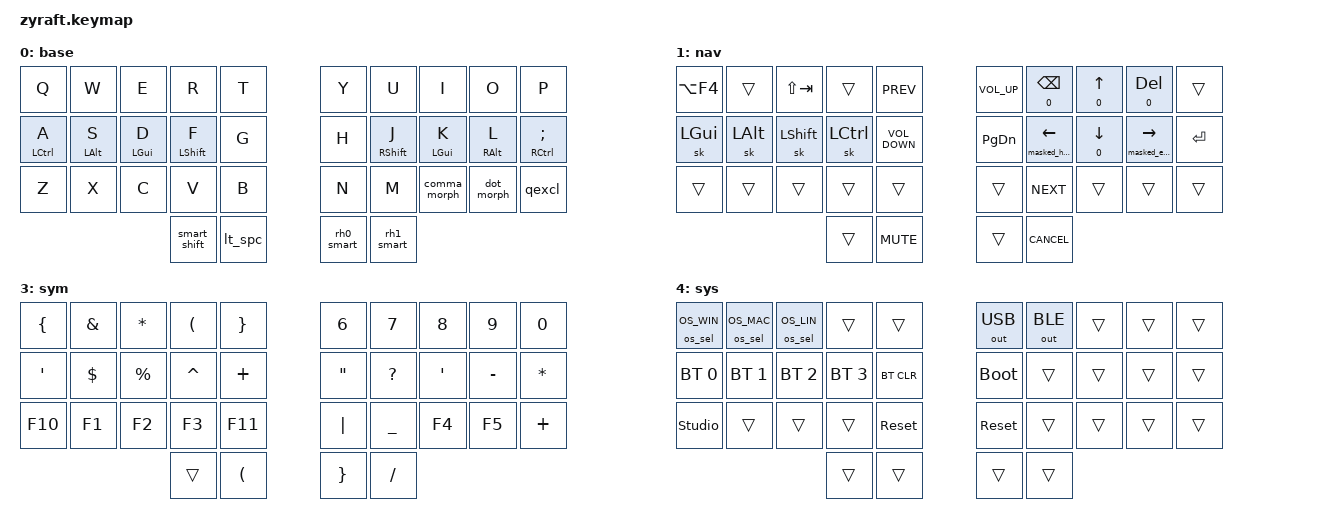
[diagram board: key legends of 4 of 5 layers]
// zyraft.keymap -- MINIMAL VERSION for keymap-editor parsing test
//
// This version strips out non-standard third-party module dependencies that
// the keymap-editor may not understand. Once we get a clean parse, we can
// re-add them incrementally.

#include <behaviors.dtsi>
#include <dt-bindings/zmk/keys.h>
#include <dt-bindings/zmk/bt.h>
#include <dt-bindings/zmk/outputs.h>

/ {
  /* ==========================================================================
   * GLOBAL DEFAULTS
   * ========================================================================== */

  &sk {
    release-after-ms = <900>;
    quick-release;
  };

  &sl {
    ignore-modifiers;
  };

  &caps_word {
    /delete-property/ ignore-modifiers;
  };

  &lt {
    flavor = "balanced";
    tapping-term-ms = <200>;
    quick-tap-ms = <175>;
  };

  /* ==========================================================================
   * BEHAVIORS -- only standard ZMK behaviors used here
   * ========================================================================== */

  behaviors {
    compatible = "zmk,behaviors";

    /* HRM left: hold = LCTRL/LSHFT/etc, tap = letter. Trigger: opposite hand + thumbs. */
    hml: home_row_mods_left {
      compatible = "zmk,behavior-hold-tap";
      label = "HRM Left";
      #binding-cells = <2>;
      bindings = <&kp>, <&kp>;
      flavor = "balanced";
      tapping-term-ms = <280>;
      quick-tap-ms = <175>;
      require-prior-idle-ms = <150>;
      hold-trigger-on-release;
      hold-trigger-key-positions = <5 6 7 8 9 15 16 17 18 19 25 26 27 28 29 30 31 32 33>;
    };

    hmr: home_row_mods_right {
      compatible = "zmk,behavior-hold-tap";
      label = "HRM Right";
      #binding-cells = <2>;
      bindings = <&kp>, <&kp>;
      flavor = "balanced";
      tapping-term-ms = <280>;
      quick-tap-ms = <175>;
      require-prior-idle-ms = <150>;
      hold-trigger-on-release;
      hold-trigger-key-positions = <0 1 2 3 4 10 11 12 13 14 20 21 22 23 24 30 31 32 33>;
    };

    /* smart_shift: tap = sticky shift, hold = held shift. */
    smart_shift: smart_shift {
      compatible = "zmk,behavior-hold-tap";
      label = "Smart Shift (sticky on tap, held on hold)";
      #binding-cells = <0>;
      bindings = <&kp LSHFT>, <&sk LSHFT>;
      flavor = "balanced";
      tapping-term-ms = <200>;
      quick-tap-ms = <175>;
      hold-trigger-key-positions = <5 6 7 8 9 15 16 17 18 19 25 26 27 28 29 30 31 32 33>;
    };

    /* mod-morph on RH0: tap = RET, with shift = TAB. */
    rh0_smart: rh0_smart {
      compatible = "zmk,behavior-mod-morph";
      label = "RET | TAB (chord)";
      #binding-cells = <0>;
      bindings = <&kp RET>, <&kp TAB>;
      mods = <(MOD_LSFT|MOD_RSFT)>;
    };

    /* mod-morph on RH1: tap = BSPC, with shift = ESC. */
    rh1_smart: rh1_smart {
      compatible = "zmk,behavior-mod-morph";
      label = "BSPC | ESC (chord)";
      #binding-cells = <0>;
      bindings = <&kp BSPC>, <&kp ESC>;
      mods = <(MOD_LSFT|MOD_RSFT)>;
    };

    /* lt_spc: tap = space, double-tap = esc, hold = NAV. */
    lt_spc: lt_spc {
      compatible = "zmk,behavior-hold-tap";
      label = "Space / Esc / NAV";
      #binding-cells = <0>;
      bindings = <&mo NAV>, <&spc_dance>;
      flavor = "balanced";
      tapping-term-ms = <200>;
      quick-tap-ms = <175>;
    };

    spc_dance: spc_dance {
      compatible = "zmk,behavior-tap-dance";
      label = "Space / Esc";
      #binding-cells = <0>;
      bindings = <&kp SPACE>, <&kp ESC>;
      tapping-term-ms = <200>;
    };

    /* Nav arrow hold-taps (masked Ctrl). */
    mt_home: mt_home {
      compatible = "zmk,behavior-hold-tap";
      label = "<- / masked Home";
      #binding-cells = <2>;
      bindings = <&masked_home>, <&kp>;
      flavor = "tap-preferred";
      tapping-term-ms = <220>;
      quick-tap-ms = <220>;
      hold-trigger-key-positions = <0>;
    };

    mt_end: mt_end {
      compatible = "zmk,behavior-hold-tap";
      label = "-> / masked End";
      #binding-cells = <2>;
      bindings = <&masked_end>, <&kp>;
      flavor = "tap-preferred";
      tapping-term-ms = <220>;
      quick-tap-ms = <220>;
      hold-trigger-key-positions = <0>;
    };

    masked_home: masked_home {
      compatible = "zmk,behavior-mod-morph";
      label = "Masked Home";
      #binding-cells = <0>;
      bindings = <&kp HOME>, <&kp HOME>;
      mods = <(MOD_LCTL)>;
    };

    masked_end: masked_end {
      compatible = "zmk,behavior-mod-morph";
      label = "Masked End";
      #binding-cells = <0>;
      bindings = <&kp END>, <&kp END>;
      mods = <(MOD_LCTL)>;
    };

    mt_up: mt_up {
      compatible = "zmk,behavior-hold-tap";
      label = "^ / masked Ctrl+Home";
      #binding-cells = <2>;
      bindings = <&kp LC(HOME)>, <&kp UP>;
      flavor = "tap-preferred";
      tapping-term-ms = <220>;
      quick-tap-ms = <220>;
      hold-trigger-key-positions = <0>;
    };

    mt_down: mt_down {
      compatible = "zmk,behavior-hold-tap";
      label = "v / masked Ctrl+End";
      #binding-cells = <2>;
      bindings = <&kp LC(END)>, <&kp DOWN>;
      flavor = "tap-preferred";
      tapping-term-ms = <220>;
      quick-tap-ms = <220>;
      hold-trigger-key-positions = <0>;
    };

    mt_bspc: mt_bspc {
      compatible = "zmk,behavior-hold-tap";
      label = "BSPC / word-bspc";
      #binding-cells = <2>;
      bindings = <&kp LC(BSPC)>, <&kp BSPC>;
      flavor = "tap-preferred";
      tapping-term-ms = <220>;
      quick-tap-ms = <220>;
      hold-trigger-key-positions = <0>;
    };

    mt_del: mt_del {
      compatible = "zmk,behavior-hold-tap";
      label = "DEL / word-del";
      #binding-cells = <2>;
      bindings = <&kp LC(DEL)>, <&kp DEL>;
      flavor = "tap-preferred";
      tapping-term-ms = <220>;
      quick-tap-ms = <220>;
      hold-trigger-key-positions = <0>;
    };

    /* Mod-morphs on bottom-right. */
    comma_morph: comma_morph {
      compatible = "zmk,behavior-mod-morph";
      label = "Comma Morph";
      #binding-cells = <0>;
      bindings = <&kp COMMA>, <&comma_inner_morph>;
      mods = <(MOD_LSFT|MOD_RSFT)>;
    };

    comma_inner_morph: comma_inner_morph {
      compatible = "zmk,behavior-mod-morph";
      label = "Comma Inner Morph";
      #binding-cells = <0>;
      bindings = <&kp SEMICOLON>, <&kp LESS_THAN>;
      mods = <(MOD_LCTL)>;
    };

    dot_morph: dot_morph {
      compatible = "zmk,behavior-mod-morph";
      label = "Dot Morph";
      #binding-cells = <0>;
      bindings = <&kp DOT>, <&dot_inner_morph>;
      mods = <(MOD_LSFT|MOD_RSFT)>;
    };

    dot_inner_morph: dot_inner_morph {
      compatible = "zmk,behavior-mod-morph";
      label = "Dot Inner Morph";
      #binding-cells = <0>;
      bindings = <&kp COLON>, <&kp GREATER_THAN>;
      mods = <(MOD_LCTL)>;
    };

    qexcl: qexcl {
      compatible = "zmk,behavior-mod-morph";
      label = "? / !";
      #binding-cells = <0>;
      bindings = <&kp QMARK>, <&kp EXCL>;
      mods = <(MOD_LSFT|MOD_RSFT)>;
    };
  };

  /* ==========================================================================
   * COMBOS -- keep simple, no layer restrictions
   * ========================================================================== */
  combos {
    compatible = "zmk,combos";

    /* Cross-thumb: NUM sticky layer. LH0=31, RH0=32 */
    num_sticky {
      timeout-ms = <50>;
      key-positions = <31 32>;
      bindings = <&sl NUM>;
    };

    /* 3-thumb: SYS layer. LH1=30, LH0=31, RH0=32 */
    sys_layer {
      timeout-ms = <50>;
      key-positions = <30 31 32>;
      bindings = <&mo SYS>;
    };

    /* Plain Tab on home-row combo. LM3=11, LM2=12 */
    tab_home {
      timeout-ms = <50>;
      key-positions = <11 12>;
      bindings = <&kp TAB>;
    };

    /* Alt+Shift+Tab (window cycling). LM3=11, LM2=12 */
    alt_shift_tab {
      timeout-ms = <50>;
      key-positions = <11 12>;
      bindings = <&hml LS(LALT) TAB>;
    };

    /* OS-aware clipboard (simple LC-based). */
    cut_combo {
      timeout-ms = <50>;
      key-positions = <21 23>;
      bindings = <&kp LC(X)>;
    };
    copy_combo {
      timeout-ms = <50>;
      key-positions = <21 22>;
      bindings = <&kp LC(INS)>;
    };
    paste_combo {
      timeout-ms = <50>;
      key-positions = <22 23>;
      bindings = <&kp LC(V)>;
    };

    /* Vertical symbol combos. */
    at_combo {
      timeout-ms = <30>;
      key-positions = <1 11>;
      bindings = <&kp AT>;
    };
    hash_combo {
      timeout-ms = <30>;
      key-positions = <2 12>;
      bindings = <&kp HASH>;
    };
    dllr_combo {
      timeout-ms = <30>;
      key-positions = <3 13>;
      bindings = <&kp DLLR>;
    };
    prcnt_combo {
      timeout-ms = <30>;
      key-positions = <4 14>;
      bindings = <&kp PRCNT>;
    };
    grave_combo {
      timeout-ms = <30>;
      key-positions = <11 21>;
      bindings = <&kp GRAVE>;
    };
    bslh_combo {
      timeout-ms = <30>;
      key-positions = <12 22>;
      bindings = <&kp BSLH>;
    };
    equal_combo {
      timeout-ms = <30>;
      key-positions = <13 23>;
      bindings = <&kp EQUAL>;
    };
    tilde_combo {
      timeout-ms = <30>;
      key-positions = <14 24>;
      bindings = <&kp TILDE>;
    };
    caret_combo {
      timeout-ms = <30>;
      key-positions = <5 15>;
      bindings = <&kp CARET>;
    };
    plus_combo {
      timeout-ms = <30>;
      key-positions = <6 16>;
      bindings = <&kp PLUS>;
    };
    star_combo {
      timeout-ms = <30>;
      key-positions = <7 17>;
      bindings = <&kp STAR>;
    };
    amps_combo {
      timeout-ms = <30>;
      key-positions = <8 18>;
      bindings = <&kp AMPS>;
    };
    under_combo {
      timeout-ms = <30>;
      key-positions = <15 25>;
      bindings = <&kp UNDER>;
    };
    minus_combo {
      timeout-ms = <30>;
      key-positions = <16 26>;
      bindings = <&kp MINUS>;
    };
    fslh_combo {
      timeout-ms = <30>;
      key-positions = <17 27>;
      bindings = <&kp FSLH>;
    };
    pipe_combo {
      timeout-ms = <30>;
      key-positions = <18 28>;
      bindings = <&kp PIPE>;
    };
  };

  /* ==========================================================================
   * KEYMAP
   * ========================================================================== */

  keymap {
    compatible = "zmk,keymap";

    base {
      bindings = <
        &kp Q       &kp W       &kp E       &kp R       &kp T          &kp Y       &kp U       &kp I       &kp O       &kp P
        &hml LCTRL A &hml LALT S &hml LGUI D &hml LSHFT F &kp G         &kp H       &hmr RSHFT J &hmr LGUI K &hmr RALT L &hmr RCTRL SEMI
        &kp Z       &kp X       &kp C       &kp V       &kp B          &kp N       &kp M       &comma_morph &dot_morph &qexcl
                                       &smart_shift &lt_spc        &rh0_smart  &rh1_smart
      >;
    };

    nav {
      bindings = <
        &kp LA(F4)   &trans      &kp LS(TAB)  &trans      &kp C_PREV    &kp C_VOL_UP   &mt_bspc 0 BSPC &mt_up 0 UP  &mt_del 0 DEL &trans
        &sk LGUI     &sk LALT    &sk LSHFT    &sk LCTRL   &kp VOL_DOWN   &kp PG_DN   &mt_home 0 LEFT &mt_down 0 DOWN &mt_end 0 RIGHT &kp RET
        &trans       &trans      &trans       &trans      &trans         &trans       &kp C_NEXT    &trans      &trans      &trans
                                       &trans       &kp C_MUTE         &trans      &kp K_CANCEL
      >;
    };

    num {
      bindings = <
        &trans       &kp N7      &kp N8      &kp N9      &trans        &trans       &trans      &trans      &trans      &trans      &trans
        &hml LGUI N0 &hml LALT N4 &hml LSHFT N5 &hml LCTRL N6 &trans     &trans       &trans      &trans      &trans      &trans      &trans
        &trans       &kp N1      &kp N2      &kp N3      &trans        &trans       &trans      &trans      &trans      &trans      &trans
                                       &trans       &trans            &trans      &trans
      >;
    };

    sym {
      bindings = <
        &kp LBRC     &kp AMPS    &kp STAR    &kp LPAR    &kp RBRC       &kp N6     &kp N7     &kp N8     &kp N9     &kp N0
        &kp SQT      &kp DLLR    &kp PRCNT   &kp CARET   &kp PLUS       &kp DQT    &kp QMARK  &kp SQT    &kp MINUS  &kp ASTRK
        &kp F10      &kp F1      &kp F2      &kp F3      &kp F11        &kp PIPE   &kp UNDER  &kp F4     &kp F5     &kp PLUS
                                       &trans       &kp LPAR          &kp RBRC   &kp FSLH
      >;
    };

    sys {
      bindings = <
        &os_sel OS_WIN &os_sel OS_MAC &os_sel OS_LIN &trans     &trans    &out OUT_USB &out OUT_BLE &trans     &trans     &trans
        &bt BT_SEL 0 &bt BT_SEL 1 &bt BT_SEL 2 &bt BT_SEL 3 &bt BT_CLR &bootloader &trans    &trans    &trans    &trans
        &studio_unlock &trans    &trans     &trans    &sys_reset    &sys_reset &trans    &trans    &trans    &trans
                                  &trans    &trans             &trans    &trans
      >;
    };
  };
};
